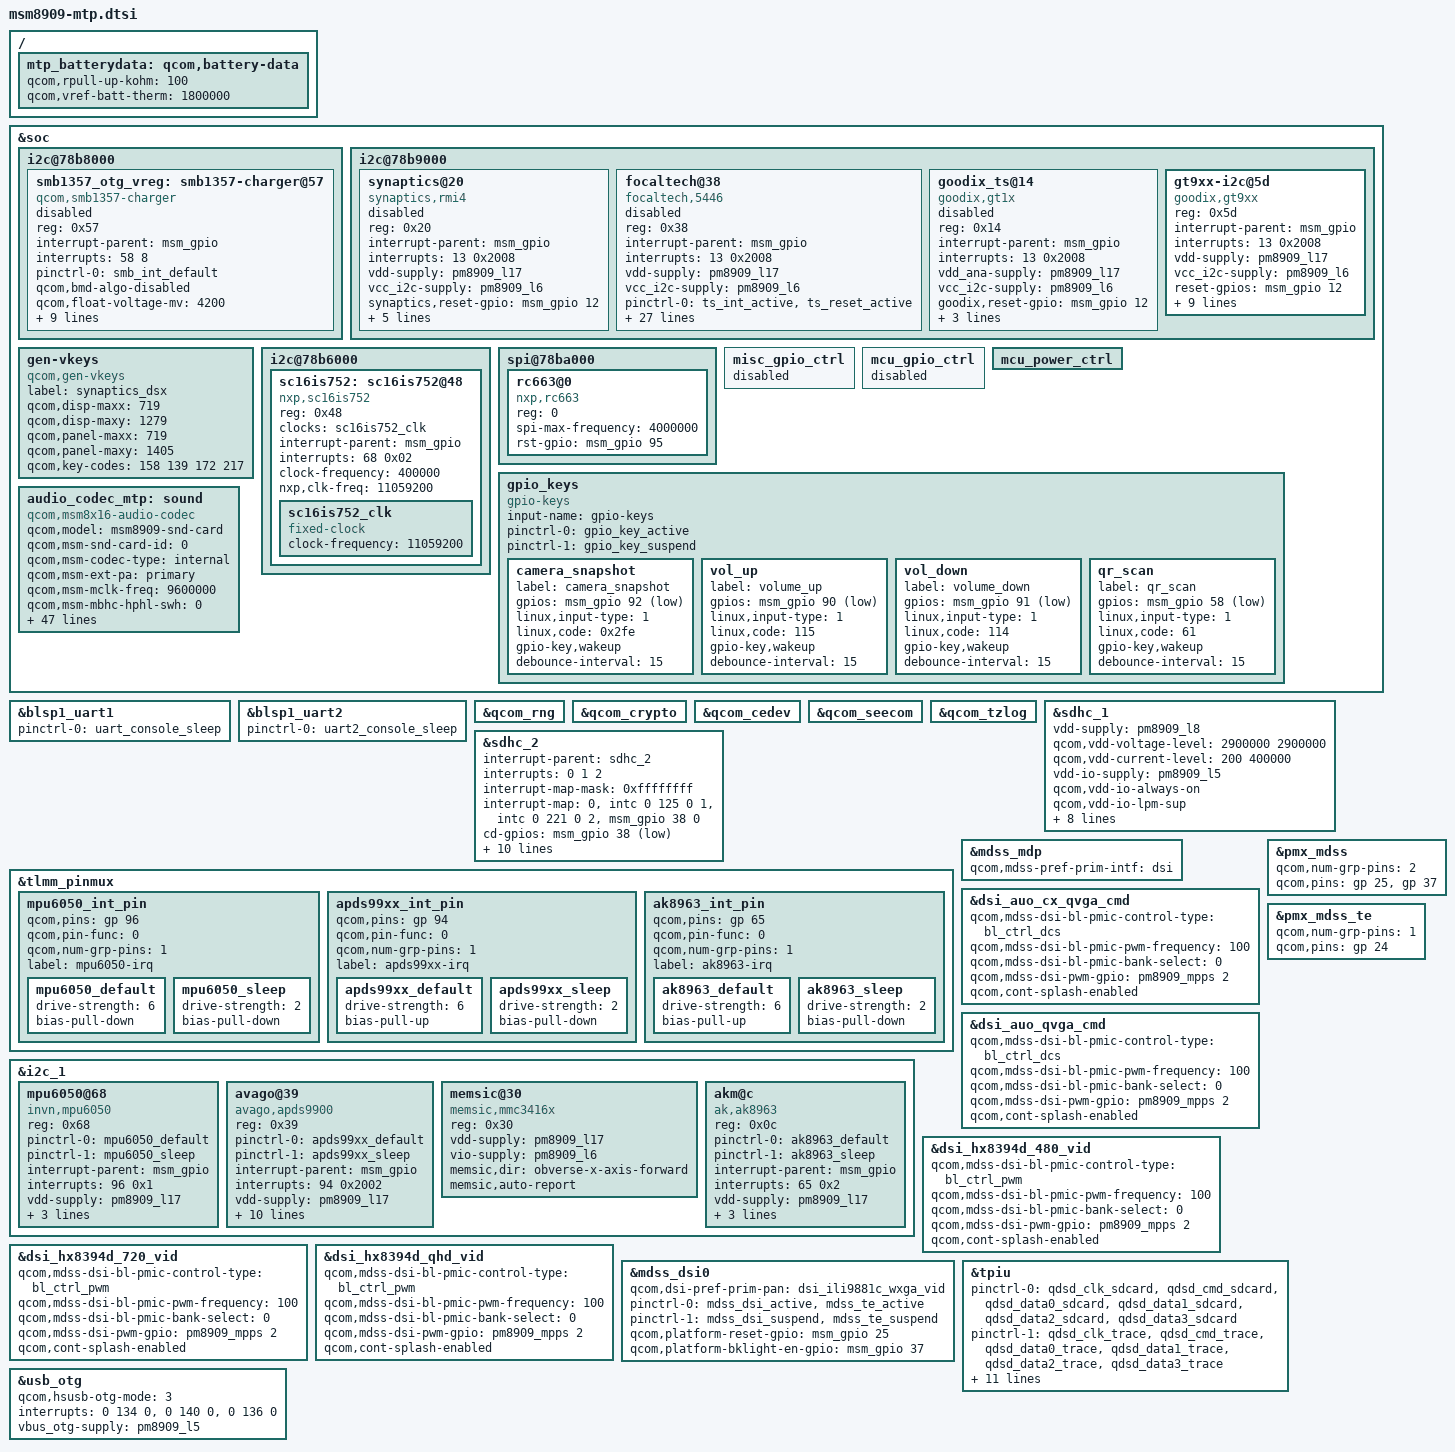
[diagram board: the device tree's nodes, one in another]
/* Copyright (c) 2014-2015, The Linux Foundation. All rights reserved.
 *
 * This program is free software; you can redistribute it and/or modify
 * it under the terms of the GNU General Public License version 2 and
 * only version 2 as published by the Free Software Foundation.
 *
 * This program is distributed in the hope that it will be useful,
 * but WITHOUT ANY WARRANTY; without even the implied warranty of
 * MERCHANTABILITY or FITNESS FOR A PARTICULAR PURPOSE.  See the
 * GNU General Public License for more details.
 */

#include "msm8909.dtsi"
#include "msm8909-pinctrl.dtsi"
#include "msm8909-camera-sensor-mtp.dtsi"

&soc {
	/*
	 * DT node to add support for SMB135x charger and integrate
	 * with VM-BMS.
	 */
	i2c@78b8000 {
		smb1357_otg_vreg: smb1357-charger@57 {
			compatible = "qcom,smb1357-charger";
			reg = <0x57>;
			interrupt-parent = <&msm_gpio>;
			interrupts = <58 8>;
			pinctrl-names = "default";
			pinctrl-0 = <&smb_int_default>;

			qcom,bmd-algo-disabled;
			qcom,float-voltage-mv = <4200>;
			qcom,charging-timeout = <1536>;
			qcom,recharge-thresh-mv = <100>;
			regulator-name = "smb1357_otg_vreg";
			qcom,soft-vfloat-comp-disabled;
			qcom,thermal-mitigation = <1500 700 600 0>;

			qcom,bms-psy-name = "bms";

			/*
			 * Disable SMB1357 based charging termination as BMS
			 * controls charging.
			 */
			qcom,iterm-disabled;

			/*
			 * Disable charge inhibit feature to start chargin on
			 * charger insertion independent of battery voltage.
			 */
			qcom,inhibit-disabled;

			/* BMS is controlling charging/re-charge */
			qcom,bms-controlled-charging;

			/*
			 * To enable charger node:
			 * set status = "ok" and
			 * add 'qcom,use-external-charger' to pm8909_chg node
			 */
			status = "disabled";
		};
	};

	i2c@78b9000 { /* BLSP1 QUP5 */
		synaptics@20 {
			status = "disabled";
			compatible = "synaptics,rmi4";
			reg = <0x20>;
			interrupt-parent = <&msm_gpio>;
			interrupts = <13 0x2008>;
			vdd-supply = <&pm8909_l17>;
			vcc_i2c-supply = <&pm8909_l6>;
			synaptics,reset-gpio = <&msm_gpio 12 0x00>;
			synaptics,irq-gpio = <&msm_gpio 13 0x2008>;
			synaptics,display-coords = <0 0 720 1280>;   //<0 0 540 960>;
			synaptics,i2c-pull-up;
			//synaptics,button-map = <139 102 158>;
			//synaptics,name = "rmi4";
			synaptics,power-down;
			synaptics,disable-gpios;
		};
		focaltech@38 {
			//status = "ok";
            status = "disabled";
			compatible = "focaltech,5446";		// ft5446
			//compatible = "focaltech,5435";	// ft5436
			reg = <0x38>;   // 0x70>>1=0x38
			interrupt-parent = <&msm_gpio>;//<&tlmm>;
			interrupts = <13 0x2008>;//<65 0x2>;
			vdd-supply = <&pm8909_l17>;//<&pm8953_l10>;
			vcc_i2c-supply = <&pm8909_l6>;//<&pm8953_l6>;
			/* pins used by touchscreen */
			pinctrl-names = "pmx_ts_active","pmx_ts_suspend","pmx_ts_release";
			pinctrl-0 = <&ts_int_active &ts_reset_active>;
			pinctrl-1 = <&ts_int_suspend &ts_reset_suspend>;
			pinctrl-2 = <&ts_release>;
			focaltech,name = "ft5435";
			focaltech,family-id = <0x54>;
			focaltech,reset-gpio = <&msm_gpio 12 0x00>;//<&tlmm 64 0x0>;
			focaltech,irq-gpio = <&msm_gpio 13 0x2008>;//<&tlmm 65 0x2008>;
			focaltech,display-coords = <0 0 720 1280>;//<0 0 1080 1920>;
			focaltech,panel-coords = <0 0 720 1280>;//<0 0 1080 1920>;
			focaltech,no-force-update;
			focaltech,i2c-pull-up;
			focaltech,group-id = <1>;
			focaltech,hard-reset-delay-ms = <200>;
			focaltech,soft-reset-delay-ms = <200>;
			focaltech,num-max-touches = <10>;
			focaltech,fw-delay-aa-ms = <2>;
			focaltech,fw-delay-55-ms = <2>;
			focaltech,fw-upgrade-id1 = <0x54>;
			focaltech,fw-upgrade-id2 = <0x2c>;
			focaltech,fw-delay-readid-ms = <10>;
			focaltech,fw-delay-era-flsh-ms = <2000>;
			focaltech,fw-auto-cal;
			focaltech,fw-vkey-support;
			focaltech,resume-in-workqueue;
			focaltech,num-virtual-key = <3>;
			focal,virtual_key_1 = <172 360 1350>;//<172 500 2040>;/*home*/
			focal,virtual_key_2 = <139 120 1350>;//<139 200 2040>;/*menu*/
			focal,virtual_key_3 = <158 600 1350>;//<158 800 2040>;/*back*/
		};

        goodix_ts@14 {
			//status = "ok";
            status = "disabled";
            compatible = "goodix,gt1x"; // gt5688
            reg = <0x14>;
			interrupt-parent = <&msm_gpio>;//<&tlmm>;
			interrupts = <13 0x2008>;//<65 0x2>;
			vdd_ana-supply = <&pm8909_l17>;//<&pm8953_l10>;
			vcc_i2c-supply = <&pm8909_l6>;//<&pm8953_l6>;
            goodix,reset-gpio = <&msm_gpio 12 0x00>;//<&gpio7 5 GPIO_ACTIVE_HIGH>;
            goodix,irq-gpio = <&msm_gpio 13 0x2008>;//<&gpio7 6 IRQ_TYPE_EDGE_FALLING>;
            //goodix,irq-gpio = <&msm_gpio 13 0x00>;//<&gpio7 6 IRQ_TYPE_EDGE_FALLING>;
            /*goodix,default-config0 = [
                4C D0 02 00 05 05 34 00 01 40
                00 0F 64 46 53 11 00 00 00 00
                14 18 1A 1E 0A 04 00 00 00 00
                00 00 00 00 14 00 00 00 00 00
                00 00 00 64 1E 28 89 29 0A 53
                55 C5 04 60 19 62 59 03 24 00
                00 3C 78 C0 14 02 00 00 54 AE
                46 9A 50 8B 5A 80 64 76 6E 6F
                00 00 00 00 00 00 00 00 00 00
                00 00 00 00 00 00 00 14 14 03
                04 00 21 64 0A 00 00 00 00 00
                00 00 00 00 00 00 00 00 00 00
                00 00 00 00 00 00 00 00 00 00
                53 30 64 5A 46 00 00 00 00 00
                05 0B 04 0A 03 09 02 08 01 07
                FF FF FF FF 09 0A 0B 0C 0D 0E
                0F 10 11 08 07 06 05 04 03 02
                01 00 FF FF FF FF FF FF FF FF
                00 00 00 00 00 00 00 00 00 00
                00 00 00 00 00 00 00 00 00 00
                00 00 00 00 00 00 00 00 00 00
                00 00 00 00 00 00 00 FF FF 06
                33 00 00 00 02 00 19 28 00 00
                5A 3C 00 00 00 13 E0 93 01];
            };*/
            goodix,default-config0 = [
                98 38 04 80 07 0A 05 03 01 00 00 0F
                50 3C 53 11 00 00 00 00 14 18 1A 1D
                0A 04 00 00 00 00 00 00 53 00 14 00
                00 00 00 00 3C 0A 0A 64 1E 28 8A 2B
                0C 41 43 DF 07 60 3A 60 1A 02 24 00
                00 39 67 C0 14 02 00 00 00 A3 40 94
                48 88 4F 80 57 78 5F 71 00 00 00 18
                50 00 00 F0 50 3C FF FF 07 00 00 00
                00 14 14 03 04 00 21 64 0A 00 00 00
                00 00 00 00 00 00 00 00 00 00 00 00
                00 00 00 00 00 00 00 00 00 00 32 30
                3C 3C 1E 00 00 00 00 00 0D 06 0C 05
                0B 04 0A 03 09 02 08 01 FF FF 00 01
                02 03 04 05 06 07 08 09 0A 0B 0C 0D
                0E 0F 10 11 12 13 14 FF FF FF FF FF
                00 00 00 00 00 00 00 00 00 00 00 00
                00 00 3C 00 05 1E 00 02 2A 1E 19 14
                02 00 03 0A 05 00 00 00 00 00 00 00
                01 FF FF 86 22 02 00 00 32 05 0F 00
                00 00 50 3C 00 00 00 00 DF 1D 01];
        };
        // reference: msm8610-qrd-skuab.dtsi
		//goodix@5d {
		//	status = "ok";
		//	compatible = "goodix,gt9xx";
		//	reg = <0x5d>;
		//	interrupt-parent = <&msm_gpio>;//<&msmgpio>;
		//	interrupts = <13 0x2008>;//<1 0x2008>;
		//	reset-gpios = <&msm_gpio 12 0x00>;//<&msmgpio 0 0x00>;
		//	interrupt-gpios = <&msm_gpio 13 0x2008>;//<&msmgpio 1 0x00>;
		//	//vdd-supply = <&pm8909_l17>;//<&pm8110_l19>;
		//	vdd_ana-supply = <&pm8909_l17>;//<&pm8110_l19>;
		//	vcc_i2c-supply = <&pm8909_l6>;//<&pm8110_l14>;
		//	goodix,panel-coords = <0 0 800 1280>;//<0 0 540 980>;
		//	goodix,display-coords = <0 0 800 1280>;//<0 0 540 960>;
		//	goodix,button-map= <139 172 158>;
		//	goodix,product-id = "915";
		//	goodix,enable-power-off;
		//	goodix,cfg-data0 = [
		//		46 1C 02 C0 03 0A 05 11 01 08
		//		14 3B 46 32 03 05 00 00 00 00
		//		00 00 00 00 00 00 00 8A 09 0B
		//		39 00 99 0A 00 00 02 83 03 1D
		//		00 08 00 00 00 00 00 00 00 00
		//		00 1D 73 94 C5 02 07 00 00 04
		//		78 21 00 5C 2C 00 48 3A 00 3A
		//		4C 00 2F 65 00 30 10 30 50 00
		//		56 45 35 FF FF 17 00 00 00 00
		//		00 01 1C 15 0C 14 5F 03 02 00
		//		00 00 00 00 00 00 00 00 00 00
		//		00 00 16 14 12 10 0E 0C 0A 08
		//		06 04 02 FF FF FF 00 00 00 00
		//		00 00 00 00 00 00 00 00 00 00
		//		00 00 22 21 20 1F 1E 1D 1C 18
		//		16 12 10 0F 0C 0A 08 06 04 02
		//		00 FF FF FF FF FF FF FF 00 00
		//		00 FF FF FF FF FF FF FF FF FF
		//		F8 FF FF FF E4 01];
		//	goodix,have-touch-key;
		//	//goodix,driver-send-cfg;
        //};
        gt9xx-i2c@5d {
            compatible = "goodix,gt9xx";
            reg = <0x5d>; 
            status = "okay";
			interrupt-parent = <&msm_gpio>;//<&tlmm>;
			interrupts = <13 0x2008>;//<65 0x2>;
			vdd-supply = <&pm8909_l17>;//<&pm8953_l10>;
			vcc_i2c-supply = <&pm8909_l6>;//<&pm8953_l6>;
            //pinctrl-names = "default", "int-output-low","int-output-high", "int-input";
            //pinctrl-0 = <&ts_int_default>;
            //pinctrl-1 = <&ts_int_output_low>;
            //pinctrl-2 = <&ts_int_output_high>;
            //pinctrl-3 = <&ts_int_input>;

            reset-gpios = <&msm_gpio 12 0x0>;
            irq-gpios = <&msm_gpio 13 0x2008>;
            irq-flags = <2>;

            touchscreen-max-id = <11>;
            touchscreen-size-x = <800>;//<1080>;
            touchscreen-size-y = <1280>;//<1920>;
            touchscreen-max-w = <512>;
            touchscreen-max-p = <512>;
            touchscreen-key-map = <139>, <172>, <158>; /*KEY_HOMEPAGE=172, KEY_BACK=158，KEY_MENU=139*/

            //goodix,type-a-report = <0>;
            //goodix,driver-send-cfg = <0>;
            //goodix,create-wr-node = <1>;
            //goodix,wakeup-with-reset = <0>;
            //goodix,resume-in-workqueue = <0>;
            goodix,int-sync = <1>;
            //goodix,swap-x2y = <0>;
            //goodix,esd-protect = <1>;
            //goodix,auto-update-cfg = <0>;
            //goodix,power-off-sleep = <0>;
            //goodix,pen-suppress-finger = <0>;
            //goodix.cfg-group0 = [
            //    53 D0 02 00 05 05 F5 D5 21 48 2D 0F 5A 41 0E 05 00 00 32 32 20 00 05 14 14 1A 14 8B 2B 00
            //];
        };
	};

	gen-vkeys {
		compatible = "qcom,gen-vkeys";
		label = "synaptics_dsx";
		qcom,disp-maxx = <719>;
		qcom,disp-maxy = <1279>;
		qcom,panel-maxx = <719>;
		qcom,panel-maxy = <1405>;
		qcom,key-codes = <158 139 172 217>;
	};

	i2c@78b6000 { /* BLSP1 QUP2 */
        sc16is752: sc16is752@48 {
            status = "okay";    // disabled
            compatible = "nxp,sc16is752";
            reg = <0x48>;   // i2c address 0x90 >> 1
            clocks = <&sc16is752_clk>;//<&clk20m>;
            interrupt-parent = <&msm_gpio>;//<&gpio3>;
            interrupts = <68 0x02>;//<7 IRQ_TYPE_EDGE_FALLING>;
            //interrupts = <8 0x02>;  // IRQ_TYPE_EDGE_FALLING
            clock-frequency = <400000>;

            //gpio-controller;
            //#gpio-cells = <2>;

            nxp,clk-freq = <11059200>;  // 14.318MHz/11.0592MHz

	        sc16is752_clk: sc16is752_clk {
		        compatible = "fixed-clock";
		        #clock-cells = <0>;
		        clock-frequency = <11059200>;// 1.8432MHz/14.318MHz
	        };
        };
		//nfc-nci@e {
        //    status = "disabled";    // disable it for pn7150
		//	compatible = "qcom,nfc-nci";
		//	reg = <0x0e>;
		//	qcom,irq-gpio = <&msm_gpio 21 0x00>;
		//	qcom,dis-gpio = <&msm_gpio 20 0x00>;
		//	qcom,clk-src = "BBCLK2";
		//	interrupt-parent = <&msm_gpio>;
		//	interrupts = <21 0>;
		//	interrupt-names = "nfc_irq";
		//	pinctrl-names = "nfc_active","nfc_suspend";
		//	pinctrl-0 = <&nfc_int_active &nfc_disable_active>;
		//	pinctrl-1 = <&nfc_int_suspend &nfc_disable_suspend>;
		//	qcom,clk-gpio = <&pm8909_gpios 2 0>;
		//	clocks = <&clock_rpm clk_bb_clk2_pin>;
		//	clock-names = "ref_clk";
		//};
	};

    // 11/14/2018 ok
    //i2c@78ba000 { /* BLSP1 QUP6 */
    //    pn7150@28 { // NFC
    //        status = "okay";
    //        compatible = "nxp,pn547";
    //        reg = <0x28>;
    //        clock-frequency = <400000>;
    //        interrupt-gpios = <&msm_gpio 8 0x00>;
    //        enable-gpios = <&msm_gpio 9 0x00>;
    //    };
    //    //sc16is752: sc16is752@48 {
    //    //    status = "okay";    // disabled
    //    //    compatible = "nxp,sc16is752";
    //    //    reg = <0x48>;   // i2c address 0x90 >> 1
    //    //    clocks = <&sc16is752_clk>;//<&clk20m>;
    //    //    interrupt-parent = <&msm_gpio>;//<&gpio3>;
    //    //    //interrupts = <68 0>;//<7 IRQ_TYPE_EDGE_FALLING>;
    //    //    interrupts = <8 0x02>;  // IRQ_TYPE_EDGE_FALLING
    //    //    clock-frequency = <400000>;

    //    //    //gpio-controller;
    //    //    //#gpio-cells = <2>;

    //    //    nxp,clk-freq = <11059200>;  // 14.318MHz/11.0592MHz

	//    //    sc16is752_clk: sc16is752_clk {
	//	//        compatible = "fixed-clock";
	//	//        #clock-cells = <0>;
	//	//        clock-frequency = <11059200>;// 1.8432MHz/14.318MHz
	//    //    };
    //    //};
    //};

	spi@78ba000 { /* BLSP1 QUP6 */
        //spidev@0 {
        //    status = "okay";
        //    compatible = "rohm,dh2228fv";   // kernel/drivers/spi/spidev.c
        //    reg = <0>;
        //    spi-max-frequency = <4000000>;  // 4 MHz
        //};
        rc663@0 {
            status = "okay";
            compatible = "nxp,rc663";       // kernel/drivers/spi/rc663.c
            reg = <0>;
            spi-max-frequency = <4000000>;  // 4 MHz
            rst-gpio = <&msm_gpio 95 0x00>;
        };
    };

    misc_gpio_ctrl {
        status = "disabled";        // okay
    };

    mcu_gpio_ctrl {
        status = "disabled";        // okay
    };

    mcu_power_ctrl {
        status = "okay";
    };
    
	gpio_keys {
		compatible = "gpio-keys";
		input-name = "gpio-keys";
		pinctrl-names = "tlmm_gpio_key_active","tlmm_gpio_key_suspend";
		pinctrl-0 = <&gpio_key_active>;
		pinctrl-1 = <&gpio_key_suspend>;

		//camera_focus {
		//	label = "camera_focus";
		//	gpios = <&msm_gpio 91 0x1>;
		//	linux,input-type = <1>;
		//	linux,code = <0x210>;
		//	gpio-key,wakeup;
		//	debounce-interval = <15>;
		//};

		camera_snapshot {
			label = "camera_snapshot";
			gpios = <&msm_gpio 92 0x1>;
			linux,input-type = <1>;
			linux,code = <0x2fe>;
			gpio-key,wakeup;
			debounce-interval = <15>;
		};

		vol_up {
			label = "volume_up";
			gpios = <&msm_gpio 90 0x1>;
			linux,input-type = <1>;
			linux,code = <115>;
			gpio-key,wakeup;
			debounce-interval = <15>;
		};

		vol_down {
			label = "volume_down";
			gpios = <&msm_gpio 91 0x1>;
			linux,input-type = <1>;
			linux,code = <114>;
			gpio-key,wakeup;
			debounce-interval = <15>;
		};

        // F2 - okay
		//key_f2 {
		//	label = "key_f2";
		//	gpios = <&msm_gpio 90 0x1>;
		//	linux,input-type = <1>;         // EV_KEY
		//	linux,code = <60>;				// KEY_F2
		//	gpio-key,wakeup;
		//	debounce-interval = <15>;
		//};
        // F3 - okay
		// scancode: kernel/include/uapi/linux/input.h
		qr_scan {
			label = "qr_scan";
			gpios = <&msm_gpio 58 0x1>;
			linux,input-type = <1>;         // EV_KEY
			linux,code = <61>;				// KEY_F3
			gpio-key,wakeup;
			debounce-interval = <15>;
		};
	};

	audio_codec_mtp: sound {
		compatible = "qcom,msm8x16-audio-codec";
		qcom,model = "msm8909-snd-card";
		qcom,msm-snd-card-id = <0>;
		qcom,msm-codec-type = "internal";
		qcom,msm-ext-pa = "primary";
		qcom,msm-mclk-freq = <9600000>;
		qcom,msm-mbhc-hphl-swh = <0>;
		qcom,msm-mbhc-gnd-swh = <0>;
		qcom,msm-hs-micbias-type = "internal";
		qcom,msm-micbias1-ext-cap;
		qcom,audio-routing =
			"RX_BIAS", "MCLK",
			"SPK_RX_BIAS", "MCLK",
			"INT_LDO_H", "MCLK",
			"MIC BIAS Internal1", "Handset Mic",
			"MIC BIAS Internal2", "Headset Mic",
		/*	"MIC BIAS External", "Secondary Mic",*/
			"AMIC1", "MIC BIAS Internal1",
			"AMIC2", "MIC BIAS Internal2";
		/*	"AMIC3", "MIC BIAS External";*/
		pinctrl-names = "cdc_lines_act",
				"cdc_lines_sus";
			/*	"cross_conn_det_act",*/
			/*	"cross_conn_det_sus",*/
			/*	"vdd_spkdrv_act",*/
			/*	"vdd_spkdrv_sus";*/
		pinctrl-0 = <&cdc_pdm_lines_act>;
		pinctrl-1 = <&cdc_pdm_lines_sus>;
	/*	pinctrl-2 = <&cross_conn_det_act>;*/
	/*	pinctrl-3 = <&cross_conn_det_sus>;*/
		qcom,cdc-us-euro-gpios = <&msm_gpio 97 0>;
		asoc-platform = <&pcm0>, <&pcm1>, <&voip>, <&voice>,
				<&loopback>, <&compress>, <&hostless>,
				<&afe>, <&lsm>, <&routing>, <&lpa>,
				<&voice_svc>;
		asoc-platform-names = "msm-pcm-dsp.0", "msm-pcm-dsp.1",
				"msm-voip-dsp", "msm-pcm-voice", "msm-pcm-loopback",
				"msm-compress-dsp", "msm-pcm-hostless", "msm-pcm-afe",
				"msm-lsm-client", "msm-pcm-routing", "msm-pcm-lpa",
				"msm-voice-svc";
		asoc-cpu = <&dai_pri_auxpcm>, <&dai_hdmi>,
				<&dai_mi2s0>, <&dai_mi2s1>, <&dai_mi2s2>, <&dai_mi2s3>,
				<&sb_0_rx>, <&sb_0_tx>, <&sb_1_rx>, <&sb_1_tx>,
				<&sb_3_rx>, <&sb_3_tx>, <&sb_4_rx>, <&sb_4_tx>,
				<&bt_sco_rx>, <&bt_sco_tx>,<&bt_a2dp_rx>,
                                <&int_fm_rx>, <&int_fm_tx>,
				<&afe_pcm_rx>, <&afe_pcm_tx>, <&afe_proxy_rx>, <&afe_proxy_tx>,
				<&incall_record_rx>, <&incall_record_tx>, <&incall_music_rx>,
				<&incall_music_2_rx>;
		asoc-cpu-names = "msm-dai-q6-auxpcm.1", "msm-dai-q6-hdmi.8",
				"msm-dai-q6-mi2s.0", "msm-dai-q6-mi2s.1",
				"msm-dai-q6-mi2s.2", "msm-dai-q6-mi2s.3",
				"msm-dai-q6-dev.16384", "msm-dai-q6-dev.16385",
				"msm-dai-q6-dev.16386", "msm-dai-q6-dev.16387",
				"msm-dai-q6-dev.16390", "msm-dai-q6-dev.16391",
				"msm-dai-q6-dev.16392", "msm-dai-q6-dev.16393",
				"msm-dai-q6-dev.12288", "msm-dai-q6-dev.12289",
				"msm-dai-q6-dev.12290", "msm-dai-q6-dev.12292",
                                "msm-dai-q6-dev.12293", "msm-dai-q6-dev.224",
				"msm-dai-q6-dev.225", "msm-dai-q6-dev.241",
				"msm-dai-q6-dev.240", "msm-dai-q6-dev.32771",
				"msm-dai-q6-dev.32772", "msm-dai-q6-dev.32773",
                                "msm-dai-q6-dev.32770";
		asoc-codec = <&stub_codec>, <&pm8909_conga_dig>;
		asoc-codec-names = "msm-stub-codec.1", "tombak_codec";
	};
};

&blsp1_uart1 {
	status = "okay";
	pinctrl-names = "default";
	pinctrl-0 = <&uart_console_sleep>;
};

&blsp1_uart2 {
	status = "okay";
	pinctrl-names = "default";
	pinctrl-0 = <&uart2_console_sleep>;
};

/ {
	mtp_batterydata: qcom,battery-data {
		qcom,rpull-up-kohm = <100>;
		qcom,vref-batt-therm = <1800000>;

		//#include "batterydata-palladium.dtsi"
		#include "batterydata-mtp-5000mah.dtsi"
	};
};

&qcom_rng {
	status = "okay";
};

&qcom_crypto {
	status = "okay";
};

&qcom_cedev {
	status = "okay";
};

&qcom_seecom {
	status = "okay";
};

&qcom_tzlog {
	status = "okay";
};

&sdhc_1 {
	vdd-supply = <&pm8909_l8>;
	qcom,vdd-voltage-level = <2900000 2900000>;
	qcom,vdd-current-level = <200 400000>;

	vdd-io-supply = <&pm8909_l5>;
	qcom,vdd-io-always-on;
	qcom,vdd-io-lpm-sup;
	qcom,vdd-io-voltage-level = <1800000 1800000>;
	qcom,vdd-io-current-level = <200 60000>;

	pinctrl-names = "active", "sleep";
	pinctrl-0 = <&sdc1_clk_on &sdc1_cmd_on &sdc1_data_on>;
	pinctrl-1 = <&sdc1_clk_off &sdc1_cmd_off &sdc1_data_off>;

	qcom,bus-speed-mode = "HS200_1p8v", "DDR_1p8v";
	qcom,nonremovable;

	status = "ok";
};

&sdhc_2 {
	 #address-cells = <0>;
	interrupt-parent = <&sdhc_2>;
	interrupts = <0 1 2>;
	#interrupt-cells = <1>;
	interrupt-map-mask = <0xffffffff>;
	interrupt-map = <0 &intc 0 125 0
			1 &intc 0 221 0
			2 &msm_gpio 38 0>;
	interrupt-names = "hc_irq", "pwr_irq", "status_irq";
	cd-gpios = <&msm_gpio 38 0x1>;

	vdd-supply = <&pm8909_l11>;
	qcom,vdd-voltage-level = <1800000 2950000>;
	qcom,vdd-current-level = <15000 400000>;

	vdd-io-supply = <&pm8909_l12>;
	qcom,vdd-io-voltage-level = <1800000 2950000>;
	qcom,vdd-io-current-level = <200 50000>;

	pinctrl-names = "active", "sleep";
	pinctrl-0 = <&sdc2_clk_on &sdc2_cmd_on &sdc2_data_on &sdc2_cd_on>;
	pinctrl-1 = <&sdc2_clk_off &sdc2_cmd_off &sdc2_data_off &sdc2_cd_off>;

	status = "ok";
};

&tlmm_pinmux {
	mpu6050_int_pin {
		qcom,pins = <&gp 96>;
		qcom,pin-func = <0>;
		qcom,num-grp-pins = <1>;
		label = "mpu6050-irq";
		mpu6050_default: mpu6050_default {
			drive-strength = <6>;
			bias-pull-down;
		};
		mpu6050_sleep: mpu6050_sleep {
			drive-strength = <2>;
			bias-pull-down;
		};
	};

	apds99xx_int_pin {
		qcom,pins = <&gp 94>;
		qcom,pin-func = <0>;
		qcom,num-grp-pins = <1>;
		label = "apds99xx-irq";
		apds99xx_default: apds99xx_default {
			drive-strength = <6>;
			bias-pull-up;
		};
		apds99xx_sleep: apds99xx_sleep {
			drive-strength = <2>;
			bias-pull-down;
		};
	};

	ak8963_int_pin {
		qcom,pins = <&gp 65>;
		qcom,pin-func = <0>;
		qcom,num-grp-pins = <1>;
		label = "ak8963-irq";
		ak8963_default: ak8963_default {
			drive-strength = <6>;
			bias-pull-up;
		};
		ak8963_sleep: ak8963_sleep {
			drive-strength = <2>;
			bias-pull-down;
		};
	};
};

&i2c_1 { /* BLSP1 QUP1 */
	mpu6050@68 { /* Gyroscope and accelerometer sensor combo */
		compatible = "invn,mpu6050";
		reg = <0x68>;
		pinctrl-names = "mpu_default","mpu_sleep";
		pinctrl-0 = <&mpu6050_default>;
		pinctrl-1 = <&mpu6050_sleep>;
		interrupt-parent = <&msm_gpio>;
		interrupts = <96 0x1>;
		vdd-supply = <&pm8909_l17>;
		vlogic-supply = <&pm8909_l6>;
		invn,gpio-int = <&msm_gpio 96 0x1>;
		invn,place = "Portrait Down Back Side";
	};

	avago@39 { /* Ambient light and proximity sensor */
		compatible = "avago,apds9900";
		reg = <0x39>;
		pinctrl-names = "default","sleep";
		pinctrl-0 = <&apds99xx_default>;
		pinctrl-1 = <&apds99xx_sleep>;
		interrupt-parent = <&msm_gpio>;
		interrupts = <94 0x2002>;
		vdd-supply = <&pm8909_l17>;
		vio-supply = <&pm8909_l6>;
		avago,irq-gpio = <&msm_gpio 94 0x2002>;
		avago,ps-threshold = <600>;
		avago,ps-hysteresis-threshold = <500>;
		avago,ps-pulse = <8>;
		avago,ps-pgain = <0>;
		avago,als-B = <186>;
		avago,als-C = <75>;
		avago,als-D = <129>;
		avago,ga-value = <256>;
	};

	memsic@30 { /* Magnetic field sensor */
		compatible = "memsic,mmc3416x";
		reg = <0x30>;
		vdd-supply = <&pm8909_l17>;
		vio-supply = <&pm8909_l6>;
		memsic,dir = "obverse-x-axis-forward";
		memsic,auto-report;
	};

	akm@c { /* Magnetic field sensor */
		compatible = "ak,ak8963";
		reg = <0x0c>;
		pinctrl-names = "ak8963_default", "ak8963_sleep";
		pinctrl-0 = <&ak8963_default>;
		pinctrl-1 = <&ak8963_sleep>;
		interrupt-parent = <&msm_gpio>;
		interrupts = <65 0x2>;
		vdd-supply = <&pm8909_l17>;
		vio-supply = <&pm8909_l6>;
		ak,layout = <0x6>;
		ak,auto-report;
	};

    // 11/14/2018 ok
    //pn7150@28 { // NFC
    //    status = "okay";
    //    //status = "disabled";    // disable it for pn7150
    //    compatible = "nxp,pn547";
    //    reg = <0x28>;
    //    clock-frequency = <400000>;
    //    interrupt-gpios = <&msm_gpio 8 0x00>;
    //    enable-gpios = <&msm_gpio 9 0x00>;
    //    /* qcom,clk-src = "BBCLK2"; */
    //    /* qcom,clk-en-gpio = <&msm_gpio 0 0x00>; */
    //    /* interrupt-parent = <&msm_gpio>; */
    //    /* interrupts = <21 0>; */
    //    /* interrupt-names = "nfc_irq"; */
    //    /* pinctrl-names = "nfc_active","nfc_suspend"; */
    //    /* pinctrl-0 = <&nfc_int_active &nfc_disable_active>; */
    //    /* pinctrl-1 = <&nfc_int_suspend &nfc_disable_suspend>; */
    //    /* qcom,clk-gpio = <&pm8916_gpios 2 0>; */
    //    /* clocks = <&clock_rpm clk_bb_clk2_pin>; */
    //    /* clock-names = "ref_clk"; */
    //};
};

#include "dsi-panel-auo-qvga-cmd.dtsi"
#include "dsi-panel-auo-cx-qvga-cmd.dtsi"
#include "dsi-panel-hx8394d-480p-video.dtsi"
#include "dsi-panel-hx8394d-720p-video.dtsi"
#include "dsi-panel-hx8394d-qhd-video.dtsi"
#include "dsi-panel-hx8394f-720p-video.dtsi"
#include "dsi-panel-tm9365a-720p-video.dtsi"
#include "dsi-panel-ili9881c-wxga-video.dtsi"

&mdss_mdp {
	qcom,mdss-pref-prim-intf = "dsi";
};

&dsi_auo_cx_qvga_cmd {
        qcom,mdss-dsi-bl-pmic-control-type = "bl_ctrl_dcs";
        qcom,mdss-dsi-bl-pmic-pwm-frequency = <100>;
        qcom,mdss-dsi-bl-pmic-bank-select = <0>;
        qcom,mdss-dsi-pwm-gpio = <&pm8909_mpps 2 0>;
        qcom,cont-splash-enabled;
};

&dsi_auo_qvga_cmd {
        qcom,mdss-dsi-bl-pmic-control-type = "bl_ctrl_dcs";
        qcom,mdss-dsi-bl-pmic-pwm-frequency = <100>;
        qcom,mdss-dsi-bl-pmic-bank-select = <0>;
        qcom,mdss-dsi-pwm-gpio = <&pm8909_mpps 2 0>;
        qcom,cont-splash-enabled;
};

&dsi_hx8394d_480_vid {
        qcom,mdss-dsi-bl-pmic-control-type = "bl_ctrl_pwm";
        qcom,mdss-dsi-bl-pmic-pwm-frequency = <100>;
        qcom,mdss-dsi-bl-pmic-bank-select = <0>;
        qcom,mdss-dsi-pwm-gpio = <&pm8909_mpps 2 0>;
        qcom,cont-splash-enabled;
};

&dsi_hx8394d_720_vid {
	qcom,mdss-dsi-bl-pmic-control-type = "bl_ctrl_pwm";
	qcom,mdss-dsi-bl-pmic-pwm-frequency = <100>;
	qcom,mdss-dsi-bl-pmic-bank-select = <0>;
	qcom,mdss-dsi-pwm-gpio = <&pm8909_mpps 2 0>;
	qcom,cont-splash-enabled;
};

&dsi_hx8394d_qhd_vid {
	qcom,mdss-dsi-bl-pmic-control-type = "bl_ctrl_pwm";
	qcom,mdss-dsi-bl-pmic-pwm-frequency = <100>;
	qcom,mdss-dsi-bl-pmic-bank-select = <0>;
	qcom,mdss-dsi-pwm-gpio = <&pm8909_mpps 2 0>;
	qcom,cont-splash-enabled;
};

&pmx_mdss {
	qcom,num-grp-pins = <2>;
	qcom,pins = <&gp 25>, <&gp 37>;
};

&pmx_mdss_te {
	qcom,num-grp-pins = <1>;
	qcom,pins = <&gp 24>;
};

&mdss_dsi0 {
	//qcom,dsi-pref-prim-pan = <&dsi_hx8394d_720_vid>;
	//qcom,dsi-pref-prim-pan = <&dsi_tm9365a_720_vid>;
	//qcom,dsi-pref-prim-pan = <&dsi_hx8394f_720_vid>;
	qcom,dsi-pref-prim-pan = <&dsi_ili9881c_wxga_vid>;
	pinctrl-names = "mdss_default", "mdss_sleep";
	pinctrl-0 = <&mdss_dsi_active &mdss_te_active>;
	pinctrl-1 = <&mdss_dsi_suspend &mdss_te_suspend>;

	qcom,platform-reset-gpio = <&msm_gpio 25 0>;
	qcom,platform-bklight-en-gpio = <&msm_gpio 37 0>;
};

/* CoreSight */
&tpiu {
	pinctrl-names = "sdcard", "trace", "swduart",
			"swdtrc", "jtag", "spmi";
	/* NIDnT */
	pinctrl-0 = <&qdsd_clk_sdcard &qdsd_cmd_sdcard
		     &qdsd_data0_sdcard &qdsd_data1_sdcard
		     &qdsd_data2_sdcard &qdsd_data3_sdcard>;
	pinctrl-1 = <&qdsd_clk_trace &qdsd_cmd_trace
		     &qdsd_data0_trace &qdsd_data1_trace
		     &qdsd_data2_trace &qdsd_data3_trace>;
	pinctrl-2 = <&qdsd_cmd_swduart &qdsd_data0_swduart
		     &qdsd_data1_swduart &qdsd_data2_swduart
		     &qdsd_data3_swduart>;
	pinctrl-3 = <&qdsd_clk_swdtrc &qdsd_cmd_swdtrc
		     &qdsd_data0_swdtrc &qdsd_data1_swdtrc
		     &qdsd_data2_swdtrc &qdsd_data3_swdtrc>;
	pinctrl-4 = <&qdsd_cmd_jtag &qdsd_data0_jtag
		     &qdsd_data1_jtag &qdsd_data2_jtag
		     &qdsd_data3_jtag>;
	pinctrl-5 = <&qdsd_clk_spmi &qdsd_cmd_spmi
		     &qdsd_data0_spmi &qdsd_data3_spmi>;
};

//&i2c_6 { /* BLSP1 QUP6 */
//    pn7150@28 { // NFC
//        status = "okay";
//        compatible = "nxp,pn547";
//        reg = <0x28>;
//        clock-frequency = <400000>;
//        interrupt-gpios = <&msm_gpio 8 0x00>;
//        enable-gpios = <&msm_gpio 9 0x00>;
//        /* interrupt-parent = <&msm_gpio>; */
//        /* interrupts = <21 0>; */
//        /* interrupt-names = "nfc_irq"; */
//        /* pinctrl-names = "nfc_active","nfc_suspend"; */
//        /* pinctrl-0 = <&nfc_int_active &nfc_disable_active>; */
//        /* pinctrl-1 = <&nfc_int_suspend &nfc_disable_suspend>; */
//    };
//};


&usb_otg {
       qcom,hsusb-otg-mode = <3>;
       interrupts = <0 134 0>,<0 140 0>,<0 136 0>;
       interrupt-names = "core_irq", "async_irq", "phy_irq";
       vbus_otg-supply = <&pm8909_l5>;
};
//&android_usb {
//    status = "okay";
//	qcom,android-usb-cdrom;
//};
